# M4KQ register map
File version: 0.1
Registers are 32-bit, read-write, reset 0x0 unless marked. A register's access mark holds for its fields unless they carry their own. Offsets are from the block's base; [hi:lo] are bit positions; {n}, {i} and the like mark numbered series.

## PB — Port B
Base 0x400E0100
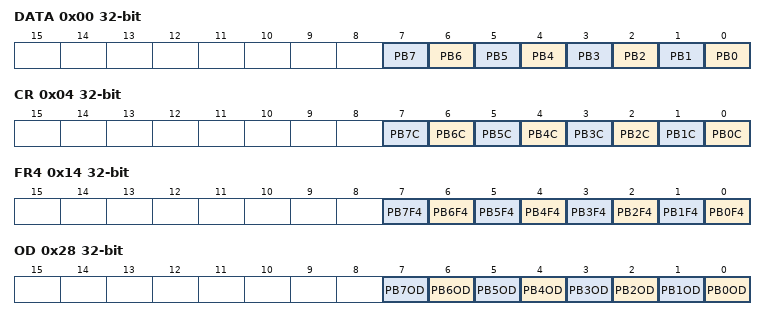
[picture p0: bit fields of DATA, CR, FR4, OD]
0x00 DATA — Port B Data Register
  [n] PB{n} (n=0..7)
0x04 CR — Port B Output Control Register
  [n] PB{n}C (n=0..7)
0x14 FR4 — Port B Function Register 4
  [n] PB{n}F4 (n=0..7)
0x18 FR5 — Port B Function Register 5
  [7] PB7F5
0x28 OD — Port B Open Drain Control Register
  [n] PB{n}OD (n=0..7)
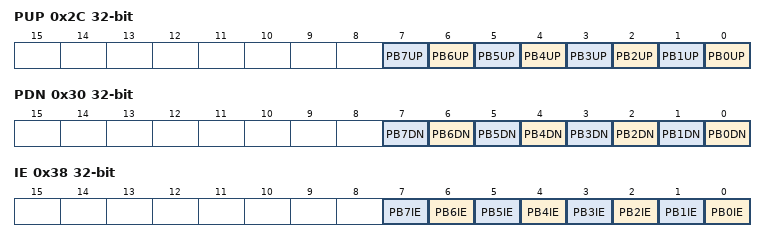
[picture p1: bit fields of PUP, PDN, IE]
0x2C PUP — Port B Pull-up Control Register
  [n] PB{n}UP (n=0..7)
0x30 PDN — Port B Pull-down Control Register
  [n] PB{n}DN (n=0..7)
0x38 IE — Port B Input Control Register
  [n] PB{n}IE (n=0..7)

## PC — Port C
Base 0x400E0200
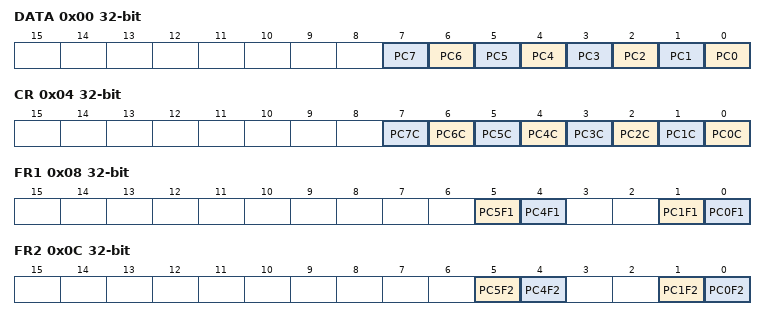
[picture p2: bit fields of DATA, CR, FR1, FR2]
0x00 DATA — Port C Data Register
  [n] PC{n} (n=0..7)
0x04 CR — Port C Output Control Register
  [n] PC{n}C (n=0..7)
0x08 FR1 — Port C Function Register 1
  [5] PC5F1, [4] PC4F1, [1] PC1F1, [0] PC0F1
0x0C FR2 — Port C Function Register 2
  [5] PC5F2, [4] PC4F2, [1] PC1F2, [0] PC0F2
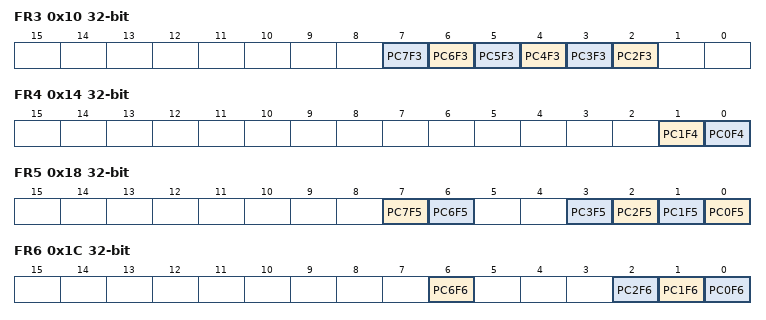
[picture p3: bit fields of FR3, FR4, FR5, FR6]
0x10 FR3 — Port C Function Register 3
  [n] PC{n}F3 (n=2..7)
0x14 FR4 — Port C Function Register 4
  [1] PC1F4, [0] PC0F4
0x18 FR5 — Port C Function Register 5
  [7] PC7F5, [6] PC6F5, [n] PC{n}F5 (n=0..3)
0x1C FR6 — Port C Function Register 6
  [6] PC6F6, [2] PC2F6, [1] PC1F6, [0] PC0F6
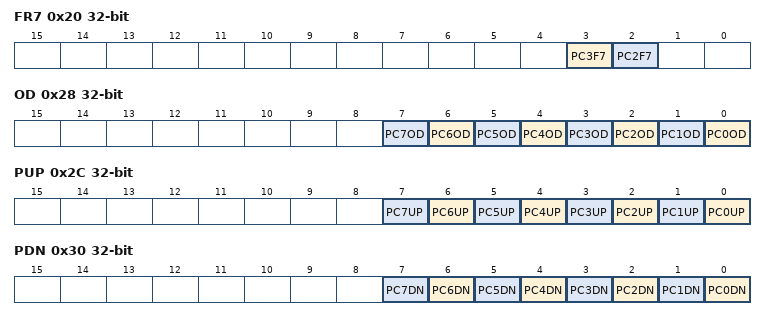
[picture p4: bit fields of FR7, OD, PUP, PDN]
0x20 FR7 — Port C Function Register 7
  [3] PC3F7, [2] PC2F7
0x28 OD — Port C Open Drain Control Register
  [n] PC{n}OD (n=0..7)
0x2C PUP — Port C Pull-up Control Register
  [n] PC{n}UP (n=0..7)
0x30 PDN — Port C Pull-down Control Register
  [n] PC{n}DN (n=0..7)
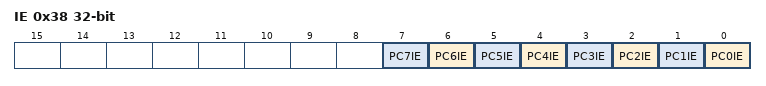
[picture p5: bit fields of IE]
0x38 IE — Port C Input Control Register
  [n] PC{n}IE (n=0..7)

## PD — Port D
Base 0x400E0300
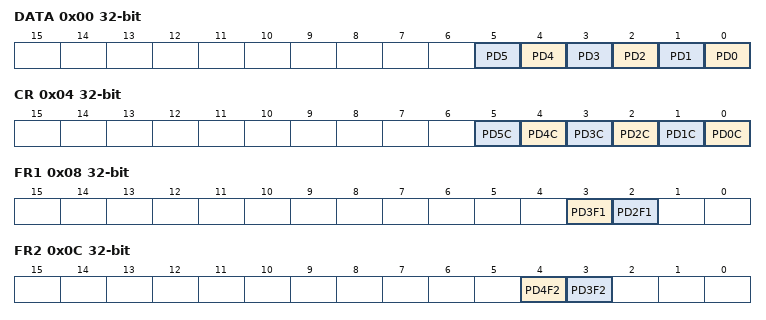
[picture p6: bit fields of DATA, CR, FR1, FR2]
0x00 DATA — Port D Data Register
  [n] PD{n} (n=0..5)
0x04 CR — Port D Output Control Register
  [n] PD{n}C (n=0..5)
0x08 FR1 — Port D Function Register 1
  [3] PD3F1, [2] PD2F1
0x0C FR2 — Port D Function Register 2
  [4] PD4F2, [3] PD3F2
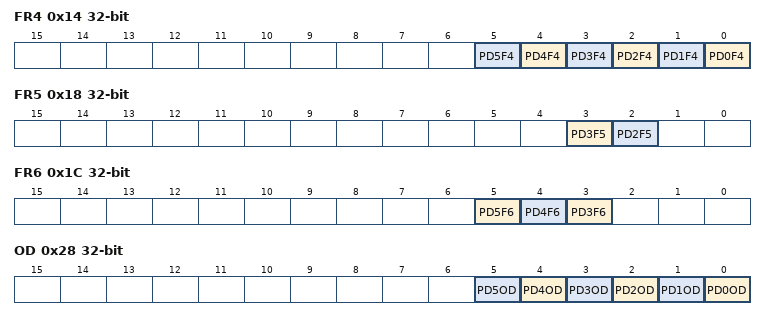
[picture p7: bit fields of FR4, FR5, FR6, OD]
0x14 FR4 — Port D Function Register 4
  [n] PD{n}F4 (n=0..5)
0x18 FR5 — Port D Function Register 5
  [3] PD3F5, [2] PD2F5
0x1C FR6 — Port D Function Register 6
  [5] PD5F6, [4] PD4F6, [3] PD3F6
0x28 OD — Port D Open Drain Control Register
  [n] PD{n}OD (n=0..5)
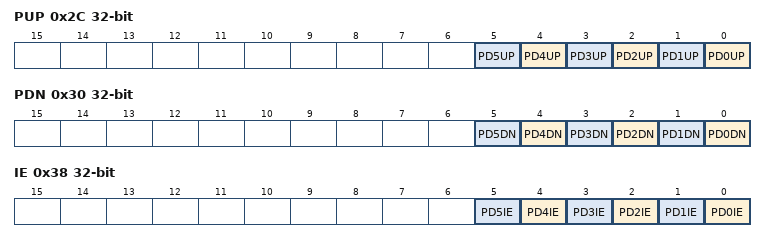
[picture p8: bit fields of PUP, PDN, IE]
0x2C PUP — Port D Pull-up Control Register
  [n] PD{n}UP (n=0..5)
0x30 PDN — Port D Pull-down Control Register
  [n] PD{n}DN (n=0..5)
0x38 IE — Port D Input Control Register
  [n] PD{n}IE (n=0..5)

## PE — Port E
Base 0x400E0400
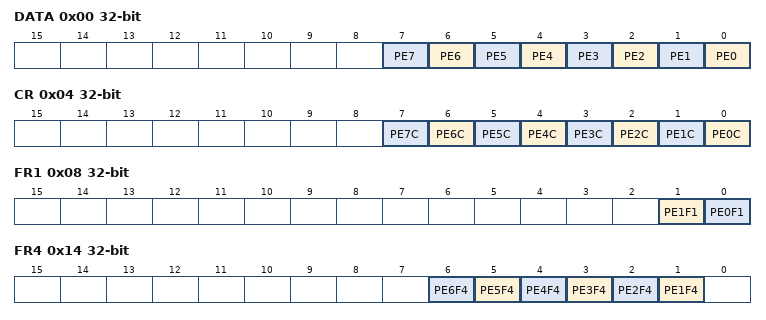
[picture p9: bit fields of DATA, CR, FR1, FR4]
0x00 DATA — Port E Data Register
  [n] PE{n} (n=0..7)
0x04 CR — Port E Output Control Register
  [n] PE{n}C (n=0..7)
0x08 FR1 — Port E Function Register 1
  [1] PE1F1, [0] PE0F1
0x14 FR4 — Port E Function Register 4
  [n] PE{n}F4 (n=1..6)
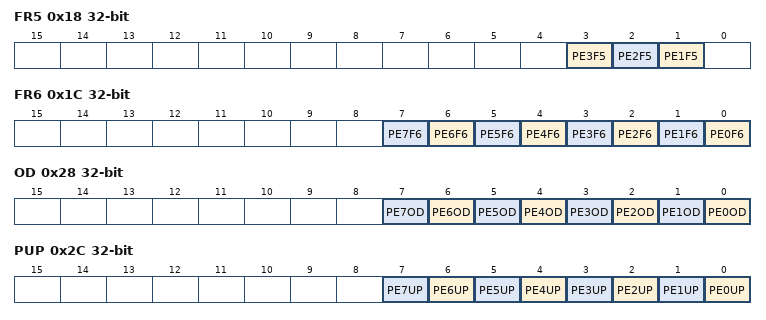
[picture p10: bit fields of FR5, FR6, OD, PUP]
0x18 FR5 — Port E Function Register 5
  [3] PE3F5, [2] PE2F5, [1] PE1F5
0x1C FR6 — Port E Function Register 6
  [n] PE{n}F6 (n=0..7)
0x20 FR7 — Port E Function Register 7
  [7] PE7F7
0x28 OD — Port E Open Drain Control Register
  [n] PE{n}OD (n=0..7)
0x2C PUP — Port E Pull-up Control Register
  [n] PE{n}UP (n=0..7)
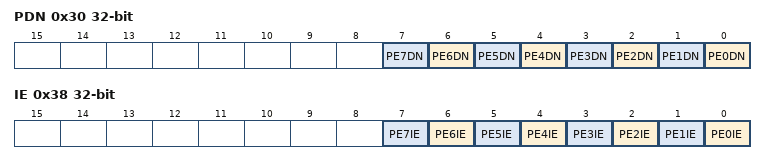
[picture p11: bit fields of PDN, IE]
0x30 PDN — Port E Pull-down Control Register
  [n] PE{n}DN (n=0..7)
0x38 IE — Port E Input Control Register
  [n] PE{n}IE (n=0..7)

## PF — Port F
Base 0x400E0500
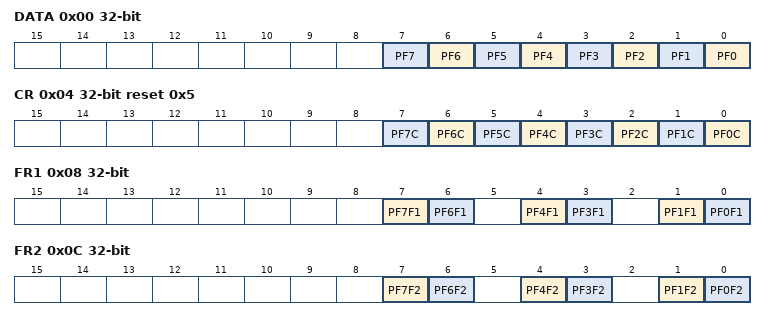
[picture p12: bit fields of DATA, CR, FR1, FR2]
0x00 DATA — Port F Data Register
  [n] PF{n} (n=0..7)
0x04 CR reset 0x5 — Port F Output Control Register
  [n] PF{n}C (n=0..7)
0x08 FR1 — Port F Function Register 1
  [7] PF7F1, [6] PF6F1, [4] PF4F1, [3] PF3F1, [1] PF1F1, [0] PF0F1
0x0C FR2 — Port F Function Register 2
  [7] PF7F2, [6] PF6F2, [4] PF4F2, [3] PF3F2, [1] PF1F2, [0] PF0F2
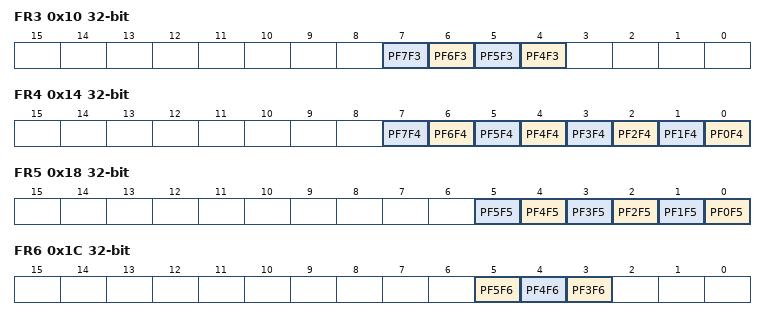
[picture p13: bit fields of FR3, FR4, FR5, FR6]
0x10 FR3 — Port F Function Register 3
  [n] PF{n}F3 (n=4..7)
0x14 FR4 — Port F Function Register 4
  [n] PF{n}F4 (n=0..7)
0x18 FR5 — Port F Function Register 5
  [n] PF{n}F5 (n=0..5)
0x1C FR6 — Port F Function Register 6
  [5] PF5F6, [4] PF4F6, [3] PF3F6
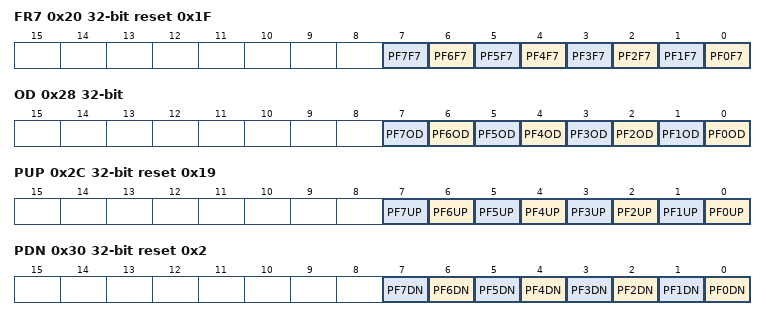
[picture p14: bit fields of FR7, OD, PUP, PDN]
0x20 FR7 reset 0x1F — Port F Function Register 7
  [n] PF{n}F7 (n=0..7)
0x28 OD — Port F Open Drain Control Register
  [n] PF{n}OD (n=0..7)
0x2C PUP reset 0x19 — Port F Pull-up Control Register
  [n] PF{n}UP (n=0..7)
0x30 PDN reset 0x2 — Port F Pull-down Control Register
  [n] PF{n}DN (n=0..7)
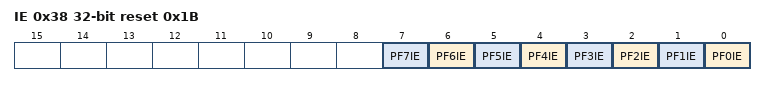
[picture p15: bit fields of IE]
0x38 IE reset 0x1B — Port F Input Control Register
  [n] PF{n}IE (n=0..7)
